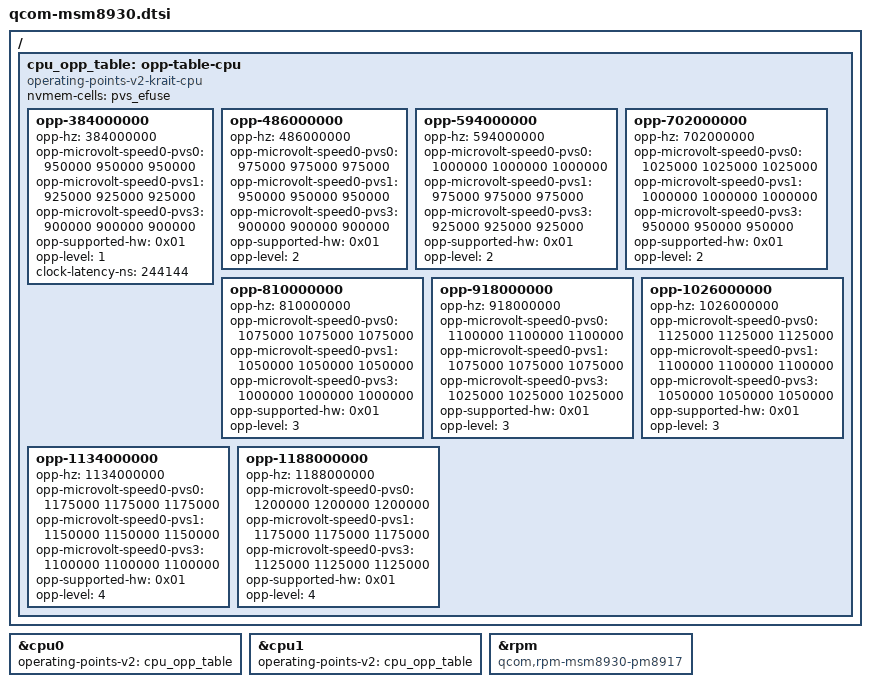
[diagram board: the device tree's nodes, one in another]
// SPDX-License-Identifier: GPL-2.0
/dts-v1/;

#include "qcom-msm8227-common.dtsi"

/ {
	cpu_opp_table: opp-table-cpu {
		compatible = "operating-points-v2-krait-cpu", "operating-points-v2";
		nvmem-cells = <&pvs_efuse>;

		/* PVS: 0 - SLOW, 1 - NOMINAL, 3 - FAST */
		/* SPEED is always 0 for MSM8227 */
		opp-384000000 {
			opp-hz = /bits/ 64 <384000000>;
			opp-microvolt-speed0-pvs0 = <950000 950000 950000>;
			opp-microvolt-speed0-pvs1 = <925000 925000 925000>;
			opp-microvolt-speed0-pvs3 = <900000 900000 900000>;
			opp-supported-hw = <0x01>;
			opp-level = <1>;
			/* give enough time to switch between PLL8 and HFPLL */
			clock-latency-ns = <244144>;
		};

		opp-486000000 {
			opp-hz = /bits/ 64 <486000000>;
			opp-microvolt-speed0-pvs0 = <975000 975000 975000>;
			opp-microvolt-speed0-pvs1 = <950000 950000 950000>;
			opp-microvolt-speed0-pvs3 = <900000 900000 900000>;
			opp-supported-hw = <0x01>;
			opp-level = <2>;
		};

		opp-594000000 {
			opp-hz = /bits/ 64 <594000000>;
			opp-microvolt-speed0-pvs0 = <1000000 1000000 1000000>;
			opp-microvolt-speed0-pvs1 = <975000 975000 975000>;
			opp-microvolt-speed0-pvs3 = <925000 925000 925000>;
			opp-supported-hw = <0x01>;
			opp-level = <2>;
		};

		opp-702000000 {
			opp-hz = /bits/ 64 <702000000>;
			opp-microvolt-speed0-pvs0 = <1025000 1025000 1025000>;
			opp-microvolt-speed0-pvs1 = <1000000 1000000 1000000>;
			opp-microvolt-speed0-pvs3 = <950000 950000 950000>;
			opp-supported-hw = <0x01>;
			opp-level = <2>;
		};

		opp-810000000 {
			opp-hz = /bits/ 64 <810000000>;
			opp-microvolt-speed0-pvs0 = <1075000 1075000 1075000>;
			opp-microvolt-speed0-pvs1 = <1050000 1050000 1050000>;
			opp-microvolt-speed0-pvs3 = <1000000 1000000 1000000>;
			opp-supported-hw = <0x01>;
			opp-level = <3>;
		};

		opp-918000000 {
			opp-hz = /bits/ 64 <918000000>;
			opp-microvolt-speed0-pvs0 = <1100000 1100000 1100000>;
			opp-microvolt-speed0-pvs1 = <1075000 1075000 1075000>;
			opp-microvolt-speed0-pvs3 = <1025000 1025000 1025000>;
			opp-supported-hw = <0x01>;
			opp-level = <3>;
		};

		opp-1026000000 {
			opp-hz = /bits/ 64 <1026000000>;
			opp-microvolt-speed0-pvs0 = <1125000 1125000 1125000>;
			opp-microvolt-speed0-pvs1 = <1100000 1100000 1100000>;
			opp-microvolt-speed0-pvs3 = <1050000 1050000 1050000>;
			opp-supported-hw = <0x01>;
			opp-level = <3>;
		};

		opp-1134000000 {
			opp-hz = /bits/ 64 <1134000000>;
			opp-microvolt-speed0-pvs0 = <1175000 1175000 1175000>;
			opp-microvolt-speed0-pvs1 = <1150000 1150000 1150000>;
			opp-microvolt-speed0-pvs3 = <1100000 1100000 1100000>;
			opp-supported-hw = <0x01>;
			opp-level = <4>;
		};

		opp-1188000000 {
			opp-hz = /bits/ 64 <1188000000>;
			opp-microvolt-speed0-pvs0 = <1200000 1200000 1200000>;
			opp-microvolt-speed0-pvs1 = <1175000 1175000 1175000>;
			opp-microvolt-speed0-pvs3 = <1125000 1125000 1125000>;
			opp-supported-hw = <0x01>;
			opp-level = <4>;
		};
	};
};

&cpu0 { operating-points-v2 = <&cpu_opp_table>; };
&cpu1 { operating-points-v2 = <&cpu_opp_table>; };

&rpm {
	compatible = "qcom,rpm-msm8930-pm8917";
};
